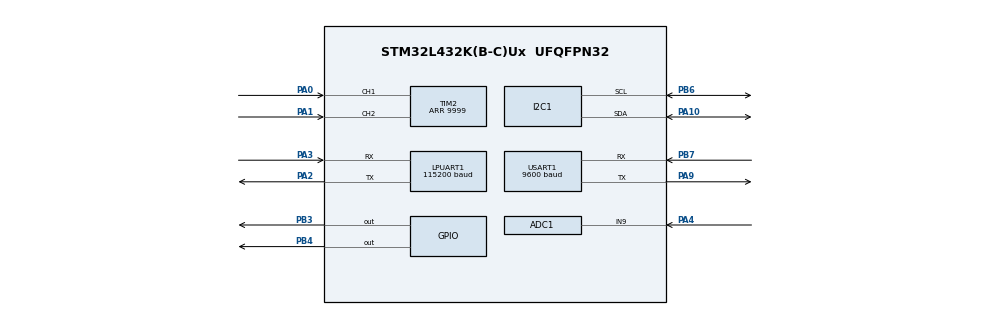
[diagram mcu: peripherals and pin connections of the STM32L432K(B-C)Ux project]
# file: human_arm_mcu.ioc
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ADC1.Channel-0\#ChannelRegularConversion=ADC_CHANNEL_9
ADC1.ExternalTrigConv=ADC_EXTERNALTRIG_T15_TRGO
ADC1.NbrOfConversion=1
ADC1.NbrOfConversionFlag=1
ADC1.OffsetNumber-0\#ChannelRegularConversion=ADC_OFFSET_NONE
ADC1.Rank-0\#ChannelRegularConversion=1
ADC1.Resolution=ADC_RESOLUTION_8B
ADC1.SamplingTime-0\#ChannelRegularConversion=ADC_SAMPLETIME_2CYCLES_5
ADC1.master=1
LPUART1.BaudRate=115200
LPUART1.WordLength=UART_WORDLENGTH_8B
Mcu.Family=STM32L4
Mcu.Name=STM32L432K(B-C)Ux
Mcu.Package=UFQFPN32
NVIC.ADC1_IRQn=true\:0\:0\:false\:false\:true\:true\:true\:true
NVIC.PriorityGroup=NVIC_PRIORITYGROUP_4
PA0.Signal=S_TIM2_CH1
PA1.Signal=S_TIM2_CH2
PA10.Mode=I2C
PA10.Signal=I2C1_SDA
PA2.Mode=Asynchronous
PA2.Signal=LPUART1_TX
PA3.Mode=Asynchronous
PA3.Signal=LPUART1_RX
PA4.Signal=ADCx_IN9
PA9.Mode=Asynchronous
PA9.Signal=USART1_TX
PB3\ (JTDO-TRACESWO).Signal=GPIO_Output
PB4\ (NJTRST).Signal=GPIO_Output
PB6.Mode=I2C
PB6.Signal=I2C1_SCL
PB7.Mode=Asynchronous
PB7.Signal=USART1_RX
ProjectManager.HeapSize=0x200
ProjectManager.StackSize=0x400
ProjectManager.TargetToolchain=STM32CubeIDE
RCC.ADCFreq_Value=32000000
RCC.HSE_VALUE=8000000
RCC.HSI48_VALUE=48000000
RCC.HSI_VALUE=16000000
RCC.LSE_VALUE=32768
RCC.MSI_VALUE=4000000
RCC.PLLSAI1N=16
RCC.USBFreq_Value=32000000
RCC.VCOOutputFreq_Value=32000000
SH.ADCx_IN9.0=ADC1_IN9,IN9-Single-Ended
SH.S_TIM2_CH1.0=TIM2_CH1,Encoder_Interface
SH.S_TIM2_CH2.0=TIM2_CH2,Encoder_Interface
TIM15.Channel-PWM\ Generation1\ No\ Output=TIM_CHANNEL_1
TIM15.Period=50000
TIM15.TIM_MasterOutputTrigger=TIM_TRGO_UPDATE
TIM2.AutoReloadPreload=TIM_AUTORELOAD_PRELOAD_ENABLE
TIM2.EncoderMode=TIM_ENCODERMODE_TI12
TIM2.Period=9999
USART1.BaudRate=9600
USART1.VirtualMode-Asynchronous=VM_ASYNC
VP_TIM15_VS_ClockSourceINT.Mode=Internal
VP_TIM15_VS_no_output1.Mode=PWM Generation1 No Output
board=custom

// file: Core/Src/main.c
/* USER CODE BEGIN Header */
/**
  ******************************************************************************
  * @file           : main.c
  * @brief          : Main program body
  ******************************************************************************
  * @attention
  *
  * Copyright (c) 2023 STMicroelectronics.
  * All rights reserved.
  *
  * This software is licensed under terms that can be found in the LICENSE file
  * in the root directory of this software component.
  * If no LICENSE file comes with this software, it is provided AS-IS.
  *
  ******************************************************************************
  */
/* USER CODE END Header */
#include "main.h"

/* USER CODE BEGIN Includes */
#include "stdio.h"
/* USER CODE END Includes */

ADC_HandleTypeDef hadc1;

I2C_HandleTypeDef hi2c1;

UART_HandleTypeDef hlpuart1;
UART_HandleTypeDef huart1;

TIM_HandleTypeDef htim2;
TIM_HandleTypeDef htim15;

void SystemClock_Config(void);
static void MX_GPIO_Init(void);
static void MX_I2C1_Init(void);
static void MX_TIM2_Init(void);
static void MX_LPUART1_UART_Init(void);
static void MX_USART1_UART_Init(void);
static void MX_ADC1_Init(void);
static void MX_TIM15_Init(void);

int main(void)
{

  /* MCU Configuration--------------------------------------------------------*/

  /* Reset of all peripherals, Initializes the Flash interface and the Systick. */
  HAL_Init();

  /* Configure the system clock */
  SystemClock_Config();

  /* Initialize all configured peripherals */
  MX_GPIO_Init();
  MX_I2C1_Init();
  MX_TIM2_Init();
  MX_LPUART1_UART_Init();
  MX_USART1_UART_Init();
  MX_ADC1_Init();
  MX_TIM15_Init();
  /* USER CODE BEGIN 2 */
  init();
  /* USER CODE END 2 */

  /* Infinite loop */
  /* USER CODE BEGIN WHILE */
  HAL_StatusTypeDef error;

  while (1)
  {
	  loop();
	  HAL_Delay(70);
    /* USER CODE END WHILE */

  }
}

void SystemClock_Config(void)
{
  RCC_OscInitTypeDef RCC_OscInitStruct = {0};
  RCC_ClkInitTypeDef RCC_ClkInitStruct = {0};

  /** Configure the main internal regulator output voltage
  */
  if (HAL_PWREx_ControlVoltageScaling(PWR_REGULATOR_VOLTAGE_SCALE1) != HAL_OK)
  {
    Error_Handler();
  }

  /** Initializes the RCC Oscillators according to the specified parameters
  * in the RCC_OscInitTypeDef structure.
  */
  RCC_OscInitStruct.OscillatorType = RCC_OSCILLATORTYPE_MSI;
  RCC_OscInitStruct.MSIState = RCC_MSI_ON;
  RCC_OscInitStruct.MSICalibrationValue = 0;
  RCC_OscInitStruct.MSIClockRange = RCC_MSIRANGE_6;
  RCC_OscInitStruct.PLL.PLLState = RCC_PLL_NONE;
  if (HAL_RCC_OscConfig(&RCC_OscInitStruct) != HAL_OK)
  {
    Error_Handler();
  }

  /** Initializes the CPU, AHB and APB buses clocks
  */
  RCC_ClkInitStruct.ClockType = RCC_CLOCKTYPE_HCLK|RCC_CLOCKTYPE_SYSCLK
                              |RCC_CLOCKTYPE_PCLK1|RCC_CLOCKTYPE_PCLK2;
  RCC_ClkInitStruct.SYSCLKSource = RCC_SYSCLKSOURCE_MSI;
  RCC_ClkInitStruct.AHBCLKDivider = RCC_SYSCLK_DIV1;
  RCC_ClkInitStruct.APB1CLKDivider = RCC_HCLK_DIV1;
  RCC_ClkInitStruct.APB2CLKDivider = RCC_HCLK_DIV1;

  if (HAL_RCC_ClockConfig(&RCC_ClkInitStruct, FLASH_LATENCY_0) != HAL_OK)
  {
    Error_Handler();
  }
}

static void MX_ADC1_Init(void)
{

  ADC_ChannelConfTypeDef sConfig = {0};

  /** Common config
  */
  hadc1.Instance = ADC1;
  hadc1.Init.ClockPrescaler = ADC_CLOCK_ASYNC_DIV1;
  hadc1.Init.Resolution = ADC_RESOLUTION_8B;
  hadc1.Init.DataAlign = ADC_DATAALIGN_RIGHT;
  hadc1.Init.ScanConvMode = ADC_SCAN_DISABLE;
  hadc1.Init.EOCSelection = ADC_EOC_SINGLE_CONV;
  hadc1.Init.LowPowerAutoWait = DISABLE;
  hadc1.Init.ContinuousConvMode = DISABLE;
  hadc1.Init.NbrOfConversion = 1;
  hadc1.Init.DiscontinuousConvMode = DISABLE;
  hadc1.Init.ExternalTrigConv = ADC_EXTERNALTRIG_T15_TRGO;
  hadc1.Init.ExternalTrigConvEdge = ADC_EXTERNALTRIGCONVEDGE_RISING;
  hadc1.Init.DMAContinuousRequests = DISABLE;
  hadc1.Init.Overrun = ADC_OVR_DATA_PRESERVED;
  hadc1.Init.OversamplingMode = DISABLE;
  if (HAL_ADC_Init(&hadc1) != HAL_OK)
  {
    Error_Handler();
  }

  /** Configure Regular Channel
  */
  sConfig.Channel = ADC_CHANNEL_9;
  sConfig.Rank = ADC_REGULAR_RANK_1;
  sConfig.SamplingTime = ADC_SAMPLETIME_2CYCLES_5;
  sConfig.SingleDiff = ADC_SINGLE_ENDED;
  sConfig.OffsetNumber = ADC_OFFSET_NONE;
  sConfig.Offset = 0;
  if (HAL_ADC_ConfigChannel(&hadc1, &sConfig) != HAL_OK)
  {
    Error_Handler();
  }

}

static void MX_I2C1_Init(void)
{

  hi2c1.Instance = I2C1;
  hi2c1.Init.Timing = 0x00000E14;
  hi2c1.Init.OwnAddress1 = 0;
  hi2c1.Init.AddressingMode = I2C_ADDRESSINGMODE_7BIT;
  hi2c1.Init.DualAddressMode = I2C_DUALADDRESS_DISABLE;
  hi2c1.Init.OwnAddress2 = 0;
  hi2c1.Init.OwnAddress2Masks = I2C_OA2_NOMASK;
  hi2c1.Init.GeneralCallMode = I2C_GENERALCALL_DISABLE;
  hi2c1.Init.NoStretchMode = I2C_NOSTRETCH_DISABLE;
  if (HAL_I2C_Init(&hi2c1) != HAL_OK)
  {
    Error_Handler();
  }

  /** Configure Analogue filter
  */
  if (HAL_I2CEx_ConfigAnalogFilter(&hi2c1, I2C_ANALOGFILTER_ENABLE) != HAL_OK)
  {
    Error_Handler();
  }

  /** Configure Digital filter
  */
  if (HAL_I2CEx_ConfigDigitalFilter(&hi2c1, 0) != HAL_OK)
  {
    Error_Handler();
  }

}

static void MX_LPUART1_UART_Init(void)
{

  hlpuart1.Instance = LPUART1;
  hlpuart1.Init.BaudRate = 115200;
  hlpuart1.Init.WordLength = UART_WORDLENGTH_8B;
  hlpuart1.Init.StopBits = UART_STOPBITS_1;
  hlpuart1.Init.Parity = UART_PARITY_NONE;
  hlpuart1.Init.Mode = UART_MODE_TX_RX;
  hlpuart1.Init.HwFlowCtl = UART_HWCONTROL_NONE;
  hlpuart1.Init.OneBitSampling = UART_ONE_BIT_SAMPLE_DISABLE;
  hlpuart1.AdvancedInit.AdvFeatureInit = UART_ADVFEATURE_NO_INIT;
  if (HAL_UART_Init(&hlpuart1) != HAL_OK)
  {
    Error_Handler();
  }

}

static void MX_USART1_UART_Init(void)
{

  huart1.Instance = USART1;
  huart1.Init.BaudRate = 9600;
  huart1.Init.WordLength = UART_WORDLENGTH_8B;
  huart1.Init.StopBits = UART_STOPBITS_1;
  huart1.Init.Parity = UART_PARITY_NONE;
  huart1.Init.Mode = UART_MODE_TX_RX;
  huart1.Init.HwFlowCtl = UART_HWCONTROL_NONE;
  huart1.Init.OverSampling = UART_OVERSAMPLING_16;
  huart1.Init.OneBitSampling = UART_ONE_BIT_SAMPLE_DISABLE;
  huart1.AdvancedInit.AdvFeatureInit = UART_ADVFEATURE_NO_INIT;
  if (HAL_UART_Init(&huart1) != HAL_OK)
  {
    Error_Handler();
  }

}

static void MX_TIM2_Init(void)
{

  TIM_Encoder_InitTypeDef sConfig = {0};
  TIM_MasterConfigTypeDef sMasterConfig = {0};

  htim2.Instance = TIM2;
  htim2.Init.Prescaler = 0;
  htim2.Init.CounterMode = TIM_COUNTERMODE_UP;
  htim2.Init.Period = 9999;
  htim2.Init.ClockDivision = TIM_CLOCKDIVISION_DIV1;
  htim2.Init.AutoReloadPreload = TIM_AUTORELOAD_PRELOAD_ENABLE;
  sConfig.EncoderMode = TIM_ENCODERMODE_TI12;
  sConfig.IC1Polarity = TIM_ICPOLARITY_RISING;
  sConfig.IC1Selection = TIM_ICSELECTION_DIRECTTI;
  sConfig.IC1Prescaler = TIM_ICPSC_DIV1;
  sConfig.IC1Filter = 0;
  sConfig.IC2Polarity = TIM_ICPOLARITY_RISING;
  sConfig.IC2Selection = TIM_ICSELECTION_DIRECTTI;
  sConfig.IC2Prescaler = TIM_ICPSC_DIV1;
  sConfig.IC2Filter = 0;
  if (HAL_TIM_Encoder_Init(&htim2, &sConfig) != HAL_OK)
  {
    Error_Handler();
  }
  sMasterConfig.MasterOutputTrigger = TIM_TRGO_RESET;
  sMasterConfig.MasterSlaveMode = TIM_MASTERSLAVEMODE_DISABLE;
  if (HAL_TIMEx_MasterConfigSynchronization(&htim2, &sMasterConfig) != HAL_OK)
  {
    Error_Handler();
  }

}

static void MX_TIM15_Init(void)
{

  TIM_ClockConfigTypeDef sClockSourceConfig = {0};
  TIM_MasterConfigTypeDef sMasterConfig = {0};
  TIM_OC_InitTypeDef sConfigOC = {0};
  TIM_BreakDeadTimeConfigTypeDef sBreakDeadTimeConfig = {0};

  htim15.Instance = TIM15;
  htim15.Init.Prescaler = 0;
  htim15.Init.CounterMode = TIM_COUNTERMODE_UP;
  htim15.Init.Period = 50000;
  htim15.Init.ClockDivision = TIM_CLOCKDIVISION_DIV1;
  htim15.Init.RepetitionCounter = 0;
  htim15.Init.AutoReloadPreload = TIM_AUTORELOAD_PRELOAD_DISABLE;
  if (HAL_TIM_Base_Init(&htim15) != HAL_OK)
  {
    Error_Handler();
  }
  sClockSourceConfig.ClockSource = TIM_CLOCKSOURCE_INTERNAL;
  if (HAL_TIM_ConfigClockSource(&htim15, &sClockSourceConfig) != HAL_OK)
  {
    Error_Handler();
  }
  if (HAL_TIM_PWM_Init(&htim15) != HAL_OK)
  {
    Error_Handler();
  }
  sMasterConfig.MasterOutputTrigger = TIM_TRGO_UPDATE;
  sMasterConfig.MasterSlaveMode = TIM_MASTERSLAVEMODE_DISABLE;
  if (HAL_TIMEx_MasterConfigSynchronization(&htim15, &sMasterConfig) != HAL_OK)
  {
    Error_Handler();
  }
  sConfigOC.OCMode = TIM_OCMODE_PWM1;
  sConfigOC.Pulse = 0;
  sConfigOC.OCPolarity = TIM_OCPOLARITY_HIGH;
  sConfigOC.OCNPolarity = TIM_OCNPOLARITY_HIGH;
  sConfigOC.OCFastMode = TIM_OCFAST_DISABLE;
  sConfigOC.OCIdleState = TIM_OCIDLESTATE_RESET;
  sConfigOC.OCNIdleState = TIM_OCNIDLESTATE_RESET;
  if (HAL_TIM_PWM_ConfigChannel(&htim15, &sConfigOC, TIM_CHANNEL_1) != HAL_OK)
  {
    Error_Handler();
  }
  sBreakDeadTimeConfig.OffStateRunMode = TIM_OSSR_DISABLE;
  sBreakDeadTimeConfig.OffStateIDLEMode = TIM_OSSI_DISABLE;
  sBreakDeadTimeConfig.LockLevel = TIM_LOCKLEVEL_OFF;
  sBreakDeadTimeConfig.DeadTime = 0;
  sBreakDeadTimeConfig.BreakState = TIM_BREAK_DISABLE;
  sBreakDeadTimeConfig.BreakPolarity = TIM_BREAKPOLARITY_HIGH;
  sBreakDeadTimeConfig.AutomaticOutput = TIM_AUTOMATICOUTPUT_DISABLE;
  if (HAL_TIMEx_ConfigBreakDeadTime(&htim15, &sBreakDeadTimeConfig) != HAL_OK)
  {
    Error_Handler();
  }

}

static void MX_GPIO_Init(void)
{
  GPIO_InitTypeDef GPIO_InitStruct = {0};

  /* GPIO Ports Clock Enable */
  __HAL_RCC_GPIOA_CLK_ENABLE();
  __HAL_RCC_GPIOB_CLK_ENABLE();

  /*Configure GPIO pin Output Level */
  HAL_GPIO_WritePin(GPIOB, GPIO_PIN_3|GPIO_PIN_4, GPIO_PIN_RESET);

  /*Configure GPIO pins : PB3 PB4 */
  GPIO_InitStruct.Pin = GPIO_PIN_3|GPIO_PIN_4;
  GPIO_InitStruct.Mode = GPIO_MODE_OUTPUT_PP;
  GPIO_InitStruct.Pull = GPIO_NOPULL;
  GPIO_InitStruct.Speed = GPIO_SPEED_FREQ_LOW;
  HAL_GPIO_Init(GPIOB, &GPIO_InitStruct);

}

/* USER CODE BEGIN 4 */

#ifdef __GNUC__
#define PUTCHAR_PROTOTYPE int __io_putchar(int ch)
#else
  #define PUTCHAR_PROTOTYPE int fputc(int ch, FILE *f)
#endif /* __GNUC__ */
PUTCHAR_PROTOTYPE
{
  HAL_UART_Transmit(&hlpuart1, (uint8_t *)&ch, 1, 0xFFFF);
  return ch;
}
/* USER CODE END 4 */

void Error_Handler(void)
{
  __disable_irq();
  while (1)
  {
  }
}
